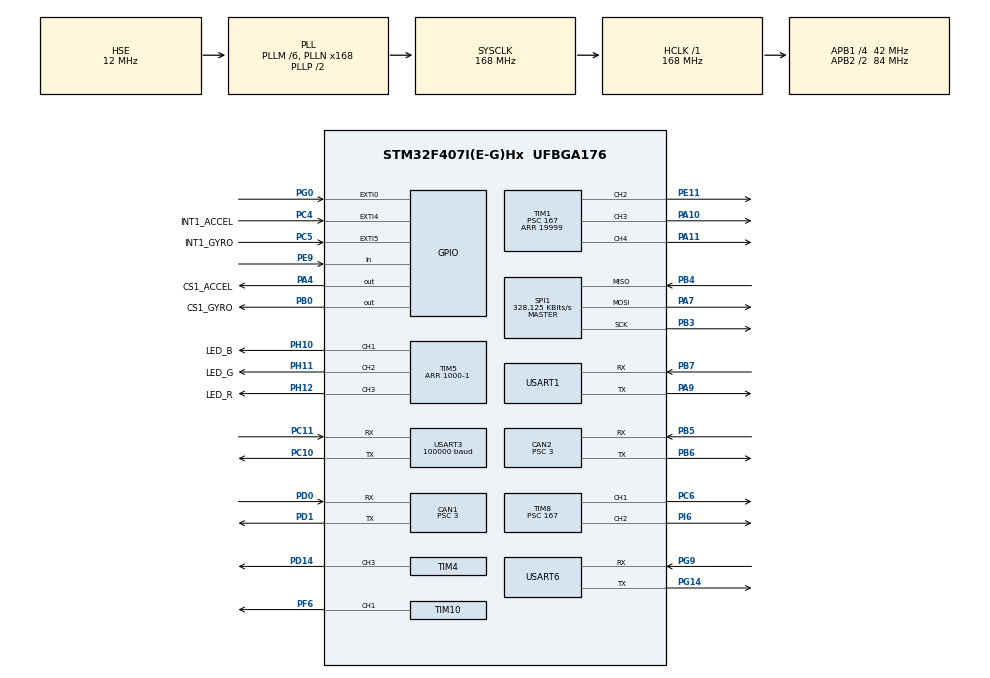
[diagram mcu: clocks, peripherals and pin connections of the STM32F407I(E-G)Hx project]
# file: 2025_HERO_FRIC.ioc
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CAN1.BS1=CAN_BS1_10TQ
CAN1.BS2=CAN_BS2_3TQ
CAN1.CalculateBaudRate=1000000
CAN1.CalculateTimeBit=1000
CAN1.CalculateTimeQuantum=71.42857142857143
CAN1.NART=DISABLE
CAN1.Prescaler=3
CAN1.TXFP=DISABLE
CAN2.BS1=CAN_BS1_10TQ
CAN2.BS2=CAN_BS2_3TQ
CAN2.CalculateBaudRate=1000000
CAN2.CalculateTimeBit=1000
CAN2.CalculateTimeQuantum=71.42857142857143
CAN2.NART=ENABLE
CAN2.Prescaler=3
Dma.Request0=SPI1_RX
Dma.Request1=SPI1_TX
Dma.Request2=USART3_RX
Dma.Request3=USART6_RX
Dma.Request4=USART6_TX
Dma.SPI1_RX.0.Direction=DMA_PERIPH_TO_MEMORY
Dma.SPI1_RX.0.FIFOMode=DMA_FIFOMODE_DISABLE
Dma.SPI1_RX.0.Instance=DMA2_Stream2
Dma.SPI1_RX.0.MemDataAlignment=DMA_MDATAALIGN_BYTE
Dma.SPI1_RX.0.MemInc=DMA_MINC_ENABLE
Dma.SPI1_RX.0.Mode=DMA_NORMAL
Dma.SPI1_RX.0.PeriphDataAlignment=DMA_PDATAALIGN_BYTE
Dma.SPI1_RX.0.PeriphInc=DMA_PINC_DISABLE
Dma.SPI1_RX.0.Priority=DMA_PRIORITY_VERY_HIGH
Dma.SPI1_TX.1.Direction=DMA_MEMORY_TO_PERIPH
Dma.SPI1_TX.1.FIFOMode=DMA_FIFOMODE_DISABLE
Dma.SPI1_TX.1.Instance=DMA2_Stream3
Dma.SPI1_TX.1.MemDataAlignment=DMA_MDATAALIGN_BYTE
Dma.SPI1_TX.1.MemInc=DMA_MINC_ENABLE
Dma.SPI1_TX.1.Mode=DMA_NORMAL
Dma.SPI1_TX.1.PeriphDataAlignment=DMA_PDATAALIGN_BYTE
Dma.SPI1_TX.1.PeriphInc=DMA_PINC_DISABLE
Dma.SPI1_TX.1.Priority=DMA_PRIORITY_HIGH
Dma.USART3_RX.2.Direction=DMA_PERIPH_TO_MEMORY
Dma.USART3_RX.2.FIFOMode=DMA_FIFOMODE_DISABLE
Dma.USART3_RX.2.Instance=DMA1_Stream1
Dma.USART3_RX.2.MemDataAlignment=DMA_MDATAALIGN_BYTE
Dma.USART3_RX.2.MemInc=DMA_MINC_ENABLE
Dma.USART3_RX.2.Mode=DMA_CIRCULAR
Dma.USART3_RX.2.PeriphDataAlignment=DMA_PDATAALIGN_BYTE
Dma.USART3_RX.2.PeriphInc=DMA_PINC_DISABLE
Dma.USART3_RX.2.Priority=DMA_PRIORITY_HIGH
Dma.USART6_RX.3.Direction=DMA_PERIPH_TO_MEMORY
Dma.USART6_RX.3.FIFOMode=DMA_FIFOMODE_DISABLE
Dma.USART6_RX.3.Instance=DMA2_Stream1
Dma.USART6_RX.3.MemDataAlignment=DMA_MDATAALIGN_BYTE
Dma.USART6_RX.3.MemInc=DMA_MINC_ENABLE
Dma.USART6_RX.3.Mode=DMA_NORMAL
Dma.USART6_RX.3.PeriphDataAlignment=DMA_PDATAALIGN_BYTE
Dma.USART6_RX.3.PeriphInc=DMA_PINC_DISABLE
Dma.USART6_RX.3.Priority=DMA_PRIORITY_HIGH
Dma.USART6_TX.4.Direction=DMA_MEMORY_TO_PERIPH
Dma.USART6_TX.4.FIFOMode=DMA_FIFOMODE_DISABLE
Dma.USART6_TX.4.Instance=DMA2_Stream6
Dma.USART6_TX.4.MemDataAlignment=DMA_MDATAALIGN_BYTE
Dma.USART6_TX.4.MemInc=DMA_MINC_ENABLE
Dma.USART6_TX.4.Mode=DMA_NORMAL
Dma.USART6_TX.4.PeriphDataAlignment=DMA_PDATAALIGN_BYTE
Dma.USART6_TX.4.PeriphInc=DMA_PINC_DISABLE
Dma.USART6_TX.4.Priority=DMA_PRIORITY_MEDIUM
FREERTOS.INCLUDE_eTaskGetState=1
FREERTOS.INCLUDE_pcTaskGetTaskName=1
FREERTOS.INCLUDE_uxTaskGetStackHighWaterMark=1
FREERTOS.INCLUDE_uxTaskGetStackHighWaterMark2=1
FREERTOS.INCLUDE_vTaskCleanUpResources=1
FREERTOS.INCLUDE_xQueueGetMutexHolder=1
FREERTOS.INCLUDE_xSemaphoreGetMutexHolder=1
FREERTOS.INCLUDE_xTaskAbortDelay=1
FREERTOS.INCLUDE_xTaskGetCurrentTaskHandle=1
FREERTOS.INCLUDE_xTaskGetHandle=1
FREERTOS.Tasks01=defaultTask,0,128,StartDefaultTask,Default,NULL,Dynamic,NULL,NULL;led_task,-2,128,LED_Task,As weak,NULL,Dynamic,NULL,NULL;buzzer_task,-2,128,Buzzer_Task,As weak,NULL,Dynamic,NULL,NULL;chassis_task,2,512,Chassis_Task,As weak,NULL,Dynamic,NULL,NULL;supercap_task,1,128,SuperCap_Task,As weak,NULL,Dynamic,NULL,NULL;referee_task,2,512,Referee_Task,As weak,NULL,Dynamic,NULL,NULL;ins_task,2,1024,Ins_Task,As weak,NULL,Dynamic,NULL,NULL;calibrate_task,0,128,Calibrate_Task,As weak,NULL,Dynamic,NULL,NULL;detect_task,2,128,Detect_Task,As weak,NULL,Dynamic,NULL,NULL;gimbal_task,2,1024,Gimbal_Task,As weak,NULL,Dynamic,NULL,NULL;telescope_task,1,128,Telescope_Task,As weak,NULL,Dynamic,NULL,NULL
FREERTOS.configTOTAL_HEAP_SIZE=20660
Mcu.Family=STM32F4
Mcu.Name=STM32F407I(E-G)Hx
Mcu.Package=UFBGA176
NVIC.CAN1_RX0_IRQn=true\:5\:0\:false\:false\:true\:true\:true\:true\:true
NVIC.CAN2_RX0_IRQn=true\:5\:0\:false\:false\:true\:true\:true\:true\:true
NVIC.DMA1_Stream1_IRQn=true\:5\:0\:false\:false\:true\:true\:false\:true\:true
NVIC.DMA2_Stream1_IRQn=true\:5\:0\:false\:false\:true\:true\:false\:true\:true
NVIC.DMA2_Stream2_IRQn=true\:5\:0\:true\:false\:false\:false\:false\:true\:true
NVIC.DMA2_Stream3_IRQn=true\:5\:0\:false\:false\:true\:true\:false\:true\:true
NVIC.DMA2_Stream6_IRQn=true\:5\:0\:false\:false\:true\:true\:false\:true\:true
NVIC.EXTI0_IRQn=true\:5\:0\:false\:false\:true\:true\:true\:true\:true
NVIC.EXTI4_IRQn=true\:5\:0\:false\:false\:true\:true\:true\:true\:true
NVIC.EXTI9_5_IRQn=true\:5\:0\:false\:false\:true\:true\:true\:true\:true
NVIC.PriorityGroup=NVIC_PRIORITYGROUP_4
NVIC.TIM3_IRQn=true\:15\:0\:false\:false\:true\:false\:false\:true\:true
NVIC.TimeBase=TIM3_IRQn
NVIC.TimeBaseIP=TIM3
NVIC.USART1_IRQn=true\:5\:0\:false\:false\:true\:true\:true\:true\:true
NVIC.USART3_IRQn=true\:5\:0\:false\:false\:false\:true\:true\:true\:true
NVIC.USART6_IRQn=true\:5\:0\:false\:false\:false\:true\:true\:true\:true
PA10.Signal=S_TIM1_CH3
PA11.Signal=S_TIM1_CH4
PA13.Mode=Serial_Wire
PA13.Signal=SYS_JTMS-SWDIO
PA14.Mode=Serial_Wire
PA14.Signal=SYS_JTCK-SWCLK
PA4.GPIO_Label=CS1_ACCEL
PA4.GPIO_PuPd=GPIO_PULLUP
PA4.GPIO_Speed=GPIO_SPEED_FREQ_HIGH
PA4.PinState=GPIO_PIN_SET
PA4.Signal=GPIO_Output
PA7.GPIO_PuPd=GPIO_PULLUP
PA7.Mode=Full_Duplex_Master
PA7.Signal=SPI1_MOSI
PA9.Mode=Asynchronous
PA9.Signal=USART1_TX
PB0.GPIO_Label=CS1_GYRO
PB0.GPIO_PuPd=GPIO_PULLUP
PB0.GPIO_Speed=GPIO_SPEED_FREQ_HIGH
PB0.PinState=GPIO_PIN_SET
PB0.Signal=GPIO_Output
PB3.GPIO_PuPd=GPIO_PULLUP
PB3.Mode=Full_Duplex_Master
PB3.Signal=SPI1_SCK
PB4.GPIO_PuPd=GPIO_PULLUP
PB4.Mode=Full_Duplex_Master
PB4.Signal=SPI1_MISO
PB5.Mode=CAN_Activate
PB5.Signal=CAN2_RX
PB6.Mode=CAN_Activate
PB6.Signal=CAN2_TX
PB7.Mode=Asynchronous
PB7.Signal=USART1_RX
PC10.Mode=Asynchronous
PC10.Signal=USART3_TX
PC11.Mode=Asynchronous
PC11.Signal=USART3_RX
PC4.GPIO_Label=INT1_ACCEL
PC4.GPIO_PuPd=GPIO_PULLUP
PC4.Signal=GPXTI4
PC5.GPIO_Label=INT1_GYRO
PC5.GPIO_PuPd=GPIO_PULLUP
PC5.Signal=GPXTI5
PC6.Signal=S_TIM8_CH1
PD0.Mode=CAN_Activate
PD0.Signal=CAN1_RX
PD1.Mode=CAN_Activate
PD1.Signal=CAN1_TX
PD14.Signal=S_TIM4_CH3
PE11.Signal=S_TIM1_CH2
PE9.GPIO_PuPd=GPIO_PULLUP
PE9.Signal=GPIO_Input
PF6.GPIO_PuPd=GPIO_PULLUP
PF6.GPIO_Speed=GPIO_SPEED_FREQ_HIGH
PF6.Signal=S_TIM10_CH1
PG0.Signal=GPXTI0
PG14.Mode=Asynchronous
PG14.Signal=USART6_TX
PG9.Mode=Asynchronous
PG9.Signal=USART6_RX
PH0-OSC_IN.Mode=HSE-External-Oscillator
PH0-OSC_IN.Signal=RCC_OSC_IN
PH1-OSC_OUT.Mode=HSE-External-Oscillator
PH1-OSC_OUT.Signal=RCC_OSC_OUT
PH10.GPIO_Label=LED_B
PH10.GPIO_PuPd=GPIO_PULLUP
PH10.Signal=S_TIM5_CH1
PH11.GPIO_Label=LED_G
PH11.GPIO_PuPd=GPIO_PULLUP
PH11.Signal=S_TIM5_CH2
PH12.GPIO_Label=LED_R
PH12.GPIO_PuPd=GPIO_PULLUP
PH12.Signal=S_TIM5_CH3
PI6.Signal=S_TIM8_CH2
ProjectManager.HeapSize=0x200
ProjectManager.StackSize=0x400
ProjectManager.TargetToolchain=MDK-ARM V5.32
RCC.48MHZClocksFreq_Value=84000000
RCC.AHBFreq_Value=168000000
RCC.APB1CLKDivider=RCC_HCLK_DIV4
RCC.APB1Freq_Value=42000000
RCC.APB1TimFreq_Value=84000000
RCC.APB2CLKDivider=RCC_HCLK_DIV2
RCC.APB2Freq_Value=84000000
RCC.APB2TimFreq_Value=168000000
RCC.CortexFreq_Value=168000000
RCC.HCLKFreq_Value=168000000
RCC.HSE_VALUE=12000000
RCC.HSI_VALUE=16000000
RCC.LSE_VALUE=32768
RCC.PLLM=6
RCC.PLLN=168
RCC.PLLSourceVirtual=RCC_PLLSOURCE_HSE
RCC.RCC_RTC_Clock_SourceVirtual=RCC_RTCCLKSOURCE_HSE_DIV30
RCC.RCC_RTC_Clock_Source_FROM_HSE=RCC_RTCCLKSOURCE_HSE_DIV30
RCC.SYSCLKFreq_VALUE=168000000
RCC.SYSCLKSource=RCC_SYSCLKSOURCE_PLLCLK
RCC.VCOOutputFreq_Value=336000000
RTC.AsynchPrediv=124
RTC.SynchPrediv=3199
SH.S_TIM10_CH1.0=TIM10_CH1,PWM Generation1 CH1
SH.S_TIM1_CH2.0=TIM1_CH2,PWM Generation2 CH2
SH.S_TIM1_CH3.0=TIM1_CH3,PWM Generation3 CH3
SH.S_TIM1_CH4.0=TIM1_CH4,PWM Generation4 CH4
SH.S_TIM4_CH3.0=TIM4_CH3,PWM Generation3 CH3
SH.S_TIM5_CH1.0=TIM5_CH1,PWM Generation1 CH1
SH.S_TIM5_CH2.0=TIM5_CH2,PWM Generation2 CH2
SH.S_TIM5_CH3.0=TIM5_CH3,PWM Generation3 CH3
SH.S_TIM8_CH1.0=TIM8_CH1,PWM Generation1 CH1
SH.S_TIM8_CH2.0=TIM8_CH2,PWM Generation2 CH2
SPI1.BaudRatePrescaler=SPI_BAUDRATEPRESCALER_256
SPI1.CLKPhase=SPI_PHASE_2EDGE
SPI1.CLKPolarity=SPI_POLARITY_HIGH
SPI1.CalculateBaudRate=328.125 KBits/s
SPI1.Direction=SPI_DIRECTION_2LINES
SPI1.Mode=SPI_MODE_MASTER
SPI1.VirtualType=VM_MASTER
TIM1.AutoReloadPreload=TIM_AUTORELOAD_PRELOAD_ENABLE
TIM1.Channel-PWM\ Generation2\ CH2=TIM_CHANNEL_2
TIM1.Channel-PWM\ Generation3\ CH3=TIM_CHANNEL_3
TIM1.Channel-PWM\ Generation4\ CH4=TIM_CHANNEL_4
TIM1.Period=19999
TIM1.Prescaler=167
TIM1.Pulse-PWM\ Generation2\ CH2=1000
TIM1.Pulse-PWM\ Generation3\ CH3=1000
TIM1.Pulse-PWM\ Generation4\ CH4=1000
TIM10.Channel=TIM_CHANNEL_1
TIM10.Period=5000-1
TIM4.Channel-PWM\ Generation3\ CH3=TIM_CHANNEL_3
TIM4.Prescaler=168-1
TIM5.Channel-PWM\ Generation1\ CH1=TIM_CHANNEL_1
TIM5.Channel-PWM\ Generation2\ CH2=TIM_CHANNEL_2
TIM5.Channel-PWM\ Generation3\ CH3=TIM_CHANNEL_3
TIM5.Period=1000-1
TIM8.Channel-PWM\ Generation1\ CH1=TIM_CHANNEL_1
TIM8.Channel-PWM\ Generation2\ CH2=TIM_CHANNEL_2
TIM8.Period=19999
TIM8.Prescaler=167
TIM8.Pulse-PWM\ Generation1\ CH1=1000
TIM8.Pulse-PWM\ Generation2\ CH2=1000
USART1.VirtualMode=VM_ASYNC
USART3.BaudRate=100000
USART3.Parity=PARITY_EVEN
USART3.VirtualMode=VM_ASYNC
USART6.VirtualMode=VM_ASYNC
VP_FREERTOS_VS_CMSIS_V1.Mode=CMSIS_V1
VP_RTC_VS_RTC_Activate.Mode=RTC_Enabled
VP_SYS_VS_tim3.Mode=TIM3
VP_TIM10_VS_ClockSourceINT.Mode=Enable_Timer
VP_TIM1_VS_ClockSourceINT.Mode=Internal
VP_TIM5_VS_ClockSourceINT.Mode=Internal
VP_TIM8_VS_ClockSourceINT.Mode=Internal
board=custom

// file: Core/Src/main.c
/* USER CODE BEGIN Header */
/**
  ******************************************************************************
  * @file           : main.c
  * @brief          : Main program body
  ******************************************************************************
  * @attention
  *
  * Copyright (c) 2024 STMicroelectronics.
  * All rights reserved.
  *
  * This software is licensed under terms that can be found in the LICENSE file
  * in the root directory of this software component.
  * If no LICENSE file comes with this software, it is provided AS-IS.
  *
  ******************************************************************************
  */
/* USER CODE END Header */
#include "main.h"
#include "cmsis_os.h"
#include "can.h"
#include "dma.h"
#include "rtc.h"
#include "spi.h"
#include "tim.h"
#include "usart.h"
#include "gpio.h"

/* USER CODE BEGIN Includes */
#include "bsp_usart.h"
#include "remote_control.h"
void can_filter_init(void);
/* USER CODE END Includes */

void SystemClock_Config(void);
void MX_FREERTOS_Init(void);

int main(void)
{

  /* MCU Configuration--------------------------------------------------------*/

  /* Reset of all peripherals, Initializes the Flash interface and the Systick. */
  HAL_Init();

  /* Configure the system clock */
  SystemClock_Config();

  /* USER CODE BEGIN SysInit */
  HAL_Delay(700);
  /* USER CODE END SysInit */

  /* Initialize all configured peripherals */
  MX_GPIO_Init();
  MX_DMA_Init();
  MX_CAN1_Init();
  MX_CAN2_Init();
  MX_SPI1_Init();
  MX_USART1_UART_Init();
  MX_USART3_UART_Init();
  MX_USART6_UART_Init();
  MX_TIM5_Init();
  MX_TIM4_Init();
  MX_TIM10_Init();
  MX_TIM1_Init();
  MX_RTC_Init();
  MX_TIM8_Init();
  /* USER CODE BEGIN 2 */
	HAL_TIM_PWM_Start(&htim4,TIM_CHANNEL_3);
  HAL_TIM_PWM_Start(&htim5,TIM_CHANNEL_1);
  HAL_TIM_PWM_Start(&htim5,TIM_CHANNEL_2);
  HAL_TIM_PWM_Start(&htim5,TIM_CHANNEL_3);
	HAL_TIM_PWM_Start(&htim10,TIM_CHANNEL_1);
  can_filter_init();
	remote_control_init();
  /* USER CODE END 2 */

  /* Call init function for freertos objects (in cmsis_os2.c) */
  MX_FREERTOS_Init();

  /* Start scheduler */
  osKernelStart();

  /* We should never get here as control is now taken by the scheduler */

  /* Infinite loop */
  while (1)
  {

  }
}

void SystemClock_Config(void)
{
  RCC_OscInitTypeDef RCC_OscInitStruct = {0};
  RCC_ClkInitTypeDef RCC_ClkInitStruct = {0};

  /** Configure the main internal regulator output voltage
  */
  __HAL_RCC_PWR_CLK_ENABLE();
  __HAL_PWR_VOLTAGESCALING_CONFIG(PWR_REGULATOR_VOLTAGE_SCALE1);

  /** Initializes the RCC Oscillators according to the specified parameters
  * in the RCC_OscInitTypeDef structure.
  */
  RCC_OscInitStruct.OscillatorType = RCC_OSCILLATORTYPE_HSE;
  RCC_OscInitStruct.HSEState = RCC_HSE_ON;
  RCC_OscInitStruct.PLL.PLLState = RCC_PLL_ON;
  RCC_OscInitStruct.PLL.PLLSource = RCC_PLLSOURCE_HSE;
  RCC_OscInitStruct.PLL.PLLM = 6;
  RCC_OscInitStruct.PLL.PLLN = 168;
  RCC_OscInitStruct.PLL.PLLP = RCC_PLLP_DIV2;
  RCC_OscInitStruct.PLL.PLLQ = 4;
  if (HAL_RCC_OscConfig(&RCC_OscInitStruct) != HAL_OK)
  {
    Error_Handler();
  }

  /** Initializes the CPU, AHB and APB buses clocks
  */
  RCC_ClkInitStruct.ClockType = RCC_CLOCKTYPE_HCLK|RCC_CLOCKTYPE_SYSCLK
                              |RCC_CLOCKTYPE_PCLK1|RCC_CLOCKTYPE_PCLK2;
  RCC_ClkInitStruct.SYSCLKSource = RCC_SYSCLKSOURCE_PLLCLK;
  RCC_ClkInitStruct.AHBCLKDivider = RCC_SYSCLK_DIV1;
  RCC_ClkInitStruct.APB1CLKDivider = RCC_HCLK_DIV4;
  RCC_ClkInitStruct.APB2CLKDivider = RCC_HCLK_DIV2;

  if (HAL_RCC_ClockConfig(&RCC_ClkInitStruct, FLASH_LATENCY_5) != HAL_OK)
  {
    Error_Handler();
  }
}

void HAL_TIM_PeriodElapsedCallback(TIM_HandleTypeDef *htim)
{
  if (htim->Instance == TIM3) {
    HAL_IncTick();
  }
}

void Error_Handler(void)
{
  __disable_irq();
  while (1)
  {
  }
}

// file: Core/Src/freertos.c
/* USER CODE BEGIN Header */
/**
  ******************************************************************************
  * File Name          : freertos.c
  * Description        : Code for freertos applications
  ******************************************************************************
  * @attention
  *
  * Copyright (c) 2024 STMicroelectronics.
  * All rights reserved.
  *
  * This software is licensed under terms that can be found in the LICENSE file
  * in the root directory of this software component.
  * If no LICENSE file comes with this software, it is provided AS-IS.
  *
  ******************************************************************************
  */
/* USER CODE END Header */

#include "FreeRTOS.h"
#include "task.h"
#include "main.h"
#include "cmsis_os.h"

osThreadId defaultTaskHandle;
osThreadId led_taskHandle;
osThreadId buzzer_taskHandle;
osThreadId chassis_taskHandle;
osThreadId supercap_taskHandle;
osThreadId referee_taskHandle;
osThreadId ins_taskHandle;
osThreadId calibrate_taskHandle;
osThreadId detect_taskHandle;
osThreadId gimbal_taskHandle;
osThreadId telescope_taskHandle;

void StartDefaultTask(void const * argument);
void LED_Task(void const * argument);
void Buzzer_Task(void const * argument);
void Chassis_Task(void const * argument);
void SuperCap_Task(void const * argument);
void Referee_Task(void const * argument);
void Ins_Task(void const * argument);
void Calibrate_Task(void const * argument);
void Detect_Task(void const * argument);
void Gimbal_Task(void const * argument);
void Telescope_Task(void const * argument);

void MX_FREERTOS_Init(void); /* (MISRA C 2004 rule 8.1) */

/* GetIdleTaskMemory prototype (linked to static allocation support) */
void vApplicationGetIdleTaskMemory( StaticTask_t **ppxIdleTaskTCBBuffer, StackType_t **ppxIdleTaskStackBuffer, uint32_t *pulIdleTaskStackSize );

/* USER CODE BEGIN GET_IDLE_TASK_MEMORY */
static StaticTask_t xIdleTaskTCBBuffer;
static StackType_t xIdleStack[configMINIMAL_STACK_SIZE];

void vApplicationGetIdleTaskMemory( StaticTask_t **ppxIdleTaskTCBBuffer, StackType_t **ppxIdleTaskStackBuffer, uint32_t *pulIdleTaskStackSize )
{
  *ppxIdleTaskTCBBuffer = &xIdleTaskTCBBuffer;
  *ppxIdleTaskStackBuffer = &xIdleStack[0];
  *pulIdleTaskStackSize = configMINIMAL_STACK_SIZE;
  /* place for user code */
}
/* USER CODE END GET_IDLE_TASK_MEMORY */

void MX_FREERTOS_Init(void) {

  /* Create the thread(s) */
  /* definition and creation of defaultTask */
  osThreadDef(defaultTask, StartDefaultTask, osPriorityNormal, 0, 128);
  defaultTaskHandle = osThreadCreate(osThread(defaultTask), NULL);

  /* definition and creation of led_task */
  osThreadDef(led_task, LED_Task, osPriorityLow, 0, 128);
  led_taskHandle = osThreadCreate(osThread(led_task), NULL);

  /* definition and creation of buzzer_task */
  osThreadDef(buzzer_task, Buzzer_Task, osPriorityLow, 0, 128);
  buzzer_taskHandle = osThreadCreate(osThread(buzzer_task), NULL);

  /* definition and creation of chassis_task */
  osThreadDef(chassis_task, Chassis_Task, osPriorityHigh, 0, 512);
  chassis_taskHandle = osThreadCreate(osThread(chassis_task), NULL);

  /* definition and creation of supercap_task */
  osThreadDef(supercap_task, SuperCap_Task, osPriorityAboveNormal, 0, 128);
  supercap_taskHandle = osThreadCreate(osThread(supercap_task), NULL);

  /* definition and creation of referee_task */
  osThreadDef(referee_task, Referee_Task, osPriorityHigh, 0, 512);
  referee_taskHandle = osThreadCreate(osThread(referee_task), NULL);

  /* definition and creation of ins_task */
  osThreadDef(ins_task, Ins_Task, osPriorityHigh, 0, 1024);
  ins_taskHandle = osThreadCreate(osThread(ins_task), NULL);

  /* definition and creation of calibrate_task */
  osThreadDef(calibrate_task, Calibrate_Task, osPriorityNormal, 0, 128);
  calibrate_taskHandle = osThreadCreate(osThread(calibrate_task), NULL);

  /* definition and creation of detect_task */
  osThreadDef(detect_task, Detect_Task, osPriorityHigh, 0, 128);
  detect_taskHandle = osThreadCreate(osThread(detect_task), NULL);

  /* definition and creation of gimbal_task */
  osThreadDef(gimbal_task, Gimbal_Task, osPriorityHigh, 0, 1024);
  gimbal_taskHandle = osThreadCreate(osThread(gimbal_task), NULL);

  /* definition and creation of telescope_task */
  osThreadDef(telescope_task, Telescope_Task, osPriorityAboveNormal, 0, 128);
  telescope_taskHandle = osThreadCreate(osThread(telescope_task), NULL);

}

void StartDefaultTask(void const * argument)
{
  for(;;)
  {
    osDelay(1);
  }
}

__weak void LED_Task(void const * argument)
{
  for(;;)
  {
    osDelay(1);
  }
}

__weak void Buzzer_Task(void const * argument)
{
  for(;;)
  {
    osDelay(1);
  }
}

__weak void Chassis_Task(void const * argument)
{
  for(;;)
  {
    osDelay(1);
  }
}

__weak void SuperCap_Task(void const * argument)
{
  for(;;)
  {
    osDelay(1);
  }
}

__weak void Referee_Task(void const * argument)
{
  for(;;)
  {
    osDelay(1);
  }
}

__weak void Ins_Task(void const * argument)
{
  for(;;)
  {
    osDelay(1);
  }
}

__weak void Calibrate_Task(void const * argument)
{
  for(;;)
  {
    osDelay(1);
  }
}

__weak void Detect_Task(void const * argument)
{
  for(;;)
  {
    osDelay(1);
  }
}

__weak void Gimbal_Task(void const * argument)
{
  for(;;)
  {
    osDelay(1);
  }
}

__weak void Telescope_Task(void const * argument)
{
  for(;;)
  {
    osDelay(1);
  }
}
